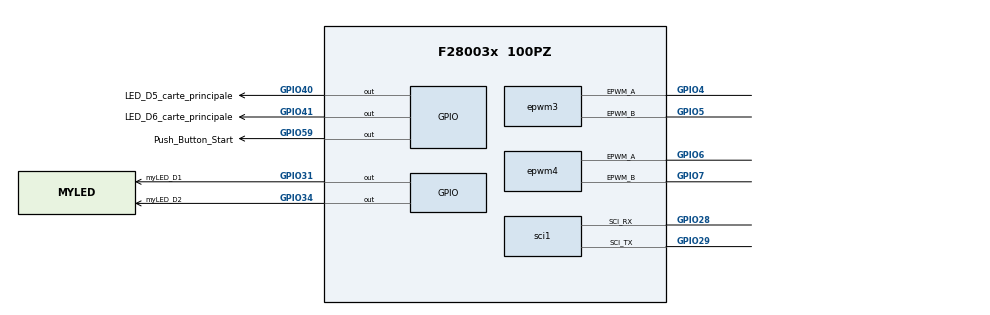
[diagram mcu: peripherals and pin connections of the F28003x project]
/**
 * @cliArgs --device "F28003x" --package "100PZ" --part "F28003x_100PZ" --context "system" --product "C2000WARE@5.02.00.00"
 * @versions {"tool":"1.19.0+3426"}
 */

/**
 * Import the modules used in this configuration.
 */
const adc              = scripting.addModule("/driverlib/adc.js", {}, false);
const adc1             = adc.addInstance();
const adc2             = adc.addInstance();
const asysctl          = scripting.addModule("/driverlib/asysctl.js");
const cputimer         = scripting.addModule("/driverlib/cputimer.js", {}, false);
const cputimer1        = cputimer.addInstance();
const epwm             = scripting.addModule("/driverlib/epwm.js", {}, false);
const epwm1            = epwm.addInstance();
const epwm2            = epwm.addInstance();
const epwm3            = epwm.addInstance();
const epwm4            = epwm.addInstance();
const gpio             = scripting.addModule("/driverlib/gpio.js", {}, false);
const gpio1            = gpio.addInstance();
const gpio2            = gpio.addInstance();
const gpio3            = gpio.addInstance();
const gpio4            = gpio.addInstance();
const gpio5            = gpio.addInstance();
const inputxbar        = scripting.addModule("/driverlib/inputxbar.js", {}, false);
const inputxbar1       = inputxbar.addInstance();
const inputxbar_input  = scripting.addModule("/driverlib/inputxbar_input.js");
const inputxbar_input1 = inputxbar_input.addInstance();
const inputxbar_input2 = inputxbar_input.addInstance();
const inputxbar_input3 = inputxbar_input.addInstance();
const sci              = scripting.addModule("/driverlib/sci.js", {}, false);
const sci1             = sci.addInstance();

/**
 * Write custom configuration values to the imported modules.
 */
adc1.$name                    = "myADC0";
adc1.adcClockPrescaler        = "ADC_CLK_DIV_2_0";
adc1.soc0Trigger              = "ADC_TRIGGER_CPU1_TINT0";
adc1.interruptPulseMode       = "ADC_PULSE_END_OF_CONV";
adc1.enabledInts              = ["ADC_INT_NUMBER1"];
adc1.registerInterrupts       = ["1"];
adc1.soc1Channel              = "ADC_CH_ADCIN1";
adc1.soc1SampleWindow         = 9;
adc1.soc1Trigger              = "ADC_TRIGGER_CPU1_TINT0";
adc1.enabledSOCs              = ["ADC_SOC_NUMBER0","ADC_SOC_NUMBER1","ADC_SOC_NUMBER2","ADC_SOC_NUMBER3"];
adc1.soc2Channel              = "ADC_CH_ADCIN2";
adc1.soc2Trigger              = "ADC_TRIGGER_CPU1_TINT0";
adc1.soc2SampleWindow         = 9;
adc1.soc3Channel              = "ADC_CH_ADCIN3";
adc1.soc3SampleWindow         = 9;
adc1.soc3Trigger              = "ADC_TRIGGER_CPU1_TINT0";
adc1.enableInterrupt1         = true;
adc1.soc0SampleWindow         = 9;
adc1.adcInt1.enableInterrupt  = true;
adc1.adcInt1.interruptHandler = "adcA1ISR";

adc2.$name              = "myADC1";
adc2.adcClockPrescaler  = "ADC_CLK_DIV_2_0";
adc2.soc0Trigger        = "ADC_TRIGGER_CPU1_TINT0";
adc2.soc0SampleWindow   = 9;
adc2.interruptPulseMode = "ADC_PULSE_END_OF_CONV";
adc2.enabledInts        = ["ADC_INT_NUMBER1"];
adc2.registerInterrupts = ["1"];
adc2.soc1Channel        = "ADC_CH_ADCIN1";
adc2.soc1SampleWindow   = 9;
adc2.soc1Trigger        = "ADC_TRIGGER_CPU1_TINT0";
adc2.enabledSOCs        = ["ADC_SOC_NUMBER0","ADC_SOC_NUMBER1","ADC_SOC_NUMBER2","ADC_SOC_NUMBER3"];
adc2.soc2Channel        = "ADC_CH_ADCIN2";
adc2.soc2Trigger        = "ADC_TRIGGER_CPU1_TINT0";
adc2.soc2SampleWindow   = 9;
adc2.soc3Channel        = "ADC_CH_ADCIN3";
adc2.soc3SampleWindow   = 9;
adc2.soc3Trigger        = "ADC_TRIGGER_CPU1_TINT0";
adc2.adcBase            = "ADCB_BASE";
adc2.useInterrupts      = false;

const analog  = scripting.addModule("/driverlib/analog.js", {}, false);
const analog1 = analog.addInstance({}, false);
analog1.$name = "myANALOGPinMux0";
adc1.analog   = analog1;
adc2.analog   = analog1;

asysctl.analogReference        = "INTERNAL";
asysctl.analogReferenceVoltage = "1P65";

cputimer1.$name           = "myCPUTIMER0";
cputimer1.emulationMode   = "CPUTIMER_EMULATIONMODE_STOPATZERO";
cputimer1.timerPrescaler  = 4;
cputimer1.startTimer      = true;
cputimer1.enableInterrupt = true;
cputimer1.timerPeriod     = 1000;

epwm1.hrpwm_edgeModeA                                          = "HRPWM_MEP_CTRL_FALLING_EDGE";
epwm1.hrpwm_edgeModeB                                          = "HRPWM_MEP_CTRL_FALLING_EDGE";
epwm1.epwmTimebase_counterMode                                 = "EPWM_COUNTER_MODE_UP";
epwm1.epwmActionQualifier_EPWM_AQ_OUTPUT_A_ON_TIMEBASE_ZERO    = "EPWM_AQ_OUTPUT_HIGH";
epwm1.epwmActionQualifier_EPWM_AQ_OUTPUT_A_ON_TIMEBASE_UP_CMPA = "EPWM_AQ_OUTPUT_LOW";
epwm1.epwmActionQualifier_EPWM_AQ_OUTPUT_B_ON_TIMEBASE_ZERO    = "EPWM_AQ_OUTPUT_HIGH";
epwm1.epwmActionQualifier_EPWM_AQ_OUTPUT_B_ON_TIMEBASE_UP_CMPA = "EPWM_AQ_OUTPUT_LOW";
epwm1.epwmTimebase_emulationMode                               = "EPWM_EMULATION_FREE_RUN";
epwm1.hrpwm_cmpaHR                                             = 50;
epwm1.hrpwm_cmpbHR                                             = 50;
epwm1.epwmDeadband_polarityFED                                 = "EPWM_DB_POLARITY_ACTIVE_LOW";
epwm1.epwmDeadband_delayRED                                    = 4;
epwm1.epwmDeadband_delayFED                                    = 4;
epwm1.epwmTimebase_clockDiv                                    = "EPWM_CLOCK_DIVIDER_8";
epwm1.epwmTimebase_hsClockDiv                                  = "EPWM_HSCLOCK_DIVIDER_1";
epwm1.epwmTimebase_period                                      = 599;
epwm1.epwmDeadband_dbControlGld                                = true;
epwm1.epwmDeadband_enableRED                                   = true;
epwm1.epwmDeadband_enableFED                                   = true;
epwm1.$name                                                    = "myEPWM1";
epwm1.epwm.$assign                                             = "EPWM1";

epwm2.hrpwm_edgeModeA                                          = "HRPWM_MEP_CTRL_FALLING_EDGE";
epwm2.hrpwm_edgeModeB                                          = "HRPWM_MEP_CTRL_FALLING_EDGE";
epwm2.epwmTimebase_counterMode                                 = "EPWM_COUNTER_MODE_UP";
epwm2.epwmActionQualifier_EPWM_AQ_OUTPUT_A_ON_TIMEBASE_ZERO    = "EPWM_AQ_OUTPUT_HIGH";
epwm2.epwmActionQualifier_EPWM_AQ_OUTPUT_A_ON_TIMEBASE_UP_CMPA = "EPWM_AQ_OUTPUT_LOW";
epwm2.epwmActionQualifier_EPWM_AQ_OUTPUT_B_ON_TIMEBASE_ZERO    = "EPWM_AQ_OUTPUT_HIGH";
epwm2.epwmActionQualifier_EPWM_AQ_OUTPUT_B_ON_TIMEBASE_UP_CMPA = "EPWM_AQ_OUTPUT_LOW";
epwm2.epwmTimebase_emulationMode                               = "EPWM_EMULATION_FREE_RUN";
epwm2.hrpwm_cmpaHR                                             = 50;
epwm2.hrpwm_cmpbHR                                             = 50;
epwm2.epwmDeadband_polarityFED                                 = "EPWM_DB_POLARITY_ACTIVE_LOW";
epwm2.epwmDeadband_delayRED                                    = 4;
epwm2.epwmDeadband_delayFED                                    = 4;
epwm2.epwmTimebase_clockDiv                                    = "EPWM_CLOCK_DIVIDER_8";
epwm2.epwmTimebase_hsClockDiv                                  = "EPWM_HSCLOCK_DIVIDER_1";
epwm2.epwmTimebase_period                                      = 599;
epwm2.epwmDeadband_dbControlGld                                = true;
epwm2.epwmDeadband_enableRED                                   = true;
epwm2.epwmDeadband_enableFED                                   = true;
epwm2.$name                                                    = "myEPWM2";
epwm2.epwm.$assign                                             = "EPWM2";

epwm3.hrpwm_edgeModeA                                          = "HRPWM_MEP_CTRL_FALLING_EDGE";
epwm3.hrpwm_edgeModeB                                          = "HRPWM_MEP_CTRL_FALLING_EDGE";
epwm3.epwmTimebase_counterMode                                 = "EPWM_COUNTER_MODE_UP";
epwm3.epwmActionQualifier_EPWM_AQ_OUTPUT_A_ON_TIMEBASE_ZERO    = "EPWM_AQ_OUTPUT_HIGH";
epwm3.epwmActionQualifier_EPWM_AQ_OUTPUT_A_ON_TIMEBASE_UP_CMPA = "EPWM_AQ_OUTPUT_LOW";
epwm3.epwmActionQualifier_EPWM_AQ_OUTPUT_B_ON_TIMEBASE_ZERO    = "EPWM_AQ_OUTPUT_HIGH";
epwm3.epwmActionQualifier_EPWM_AQ_OUTPUT_B_ON_TIMEBASE_UP_CMPA = "EPWM_AQ_OUTPUT_LOW";
epwm3.epwmTimebase_emulationMode                               = "EPWM_EMULATION_FREE_RUN";
epwm3.hrpwm_cmpaHR                                             = 50;
epwm3.hrpwm_cmpbHR                                             = 50;
epwm3.epwmDeadband_polarityFED                                 = "EPWM_DB_POLARITY_ACTIVE_LOW";
epwm3.epwmDeadband_delayRED                                    = 4;
epwm3.epwmDeadband_delayFED                                    = 4;
epwm3.epwmTimebase_clockDiv                                    = "EPWM_CLOCK_DIVIDER_8";
epwm3.epwmTimebase_hsClockDiv                                  = "EPWM_HSCLOCK_DIVIDER_1";
epwm3.epwmTimebase_period                                      = 599;
epwm3.epwmDeadband_dbControlGld                                = true;
epwm3.epwmDeadband_enableRED                                   = true;
epwm3.epwmDeadband_enableFED                                   = true;
epwm3.$name                                                    = "myEPWM3";
epwm3.epwm.$assign                                             = "EPWM3";
epwm3.epwm.epwm_aPin.$assign                                   = "GPIO4";
epwm3.epwm.epwm_bPin.$assign                                   = "GPIO5";

epwm4.hrpwm_edgeModeA                                          = "HRPWM_MEP_CTRL_FALLING_EDGE";
epwm4.hrpwm_edgeModeB                                          = "HRPWM_MEP_CTRL_FALLING_EDGE";
epwm4.epwmTimebase_counterMode                                 = "EPWM_COUNTER_MODE_UP";
epwm4.epwmActionQualifier_EPWM_AQ_OUTPUT_A_ON_TIMEBASE_ZERO    = "EPWM_AQ_OUTPUT_HIGH";
epwm4.epwmActionQualifier_EPWM_AQ_OUTPUT_A_ON_TIMEBASE_UP_CMPA = "EPWM_AQ_OUTPUT_LOW";
epwm4.epwmActionQualifier_EPWM_AQ_OUTPUT_B_ON_TIMEBASE_ZERO    = "EPWM_AQ_OUTPUT_HIGH";
epwm4.epwmActionQualifier_EPWM_AQ_OUTPUT_B_ON_TIMEBASE_UP_CMPA = "EPWM_AQ_OUTPUT_LOW";
epwm4.epwmTimebase_emulationMode                               = "EPWM_EMULATION_FREE_RUN";
epwm4.hrpwm_cmpaHR                                             = 50;
epwm4.hrpwm_cmpbHR                                             = 50;
epwm4.epwmDeadband_polarityFED                                 = "EPWM_DB_POLARITY_ACTIVE_LOW";
epwm4.epwmDeadband_delayRED                                    = 4;
epwm4.epwmDeadband_delayFED                                    = 4;
epwm4.epwmTimebase_clockDiv                                    = "EPWM_CLOCK_DIVIDER_8";
epwm4.epwmTimebase_hsClockDiv                                  = "EPWM_HSCLOCK_DIVIDER_1";
epwm4.epwmTimebase_period                                      = 599;
epwm4.epwmDeadband_dbControlGld                                = true;
epwm4.epwmDeadband_enableRED                                   = true;
epwm4.epwmDeadband_enableFED                                   = true;
epwm4.$name                                                    = "myEPWM4";
epwm4.epwm.$assign                                             = "EPWM4";
epwm4.epwm.epwm_aPin.$assign                                   = "GPIO6";
epwm4.epwm.epwm_bPin.$assign                                   = "GPIO7";

gpio1.direction       = "GPIO_DIR_MODE_OUT";
gpio1.$name           = "myLED_D1";
gpio1.gpioPin.$assign = "GPIO31";

gpio2.$name           = "myLED_D2";
gpio2.direction       = "GPIO_DIR_MODE_OUT";
gpio2.gpioPin.$assign = "GPIO34";

gpio3.$name           = "LED_D5_carte_principale";
gpio3.direction       = "GPIO_DIR_MODE_OUT";
gpio3.gpioPin.$assign = "GPIO40";

gpio4.$name           = "LED_D6_carte_principale";
gpio4.direction       = "GPIO_DIR_MODE_OUT";
gpio4.gpioPin.$assign = "GPIO41";

gpio5.$name                     = "Push_Button_Start";
gpio5.padConfig                 = "PULLUP";
gpio5.useInterrupt              = true;
gpio5.gpioPin.$assign           = "GPIO59";
gpio5.xint.enableInt            = true;
gpio5.xint.registerInterrupts   = true;
gpio5.xint.xInt.enableInterrupt = true;

inputxbar1.$name = "myINPUTXBAR5";

inputxbar_input1.$name          = "myINPUTXBARINPUT0";
inputxbar_input1.inputxbarInput = "XBAR_INPUT5";
inputxbar_input1.inputxbarGpio  = "GPIO40";

inputxbar_input2.$name          = "myINPUTXBARINPUT1";
inputxbar_input2.inputxbarInput = "XBAR_INPUT6";
inputxbar_input2.inputxbarGpio  = "GPIO40";

inputxbar_input3.$name         = "myINPUTXBARINPUT2";
gpio5.xint.inputxbar           = inputxbar_input3;
inputxbar_input3.inputxbarGpio = "GPIO59";
inputxbar_input3.inputxbarLock = true;

sci1.$name                    = "mySCI0";
sci1.registerInterrupts       = true;
sci1.rxFifo                   = "SCI_FIFO_RX1";
sci1.sci.sci_rxPin.$assign    = "GPIO28";
sci1.sci.sci_txPin.$assign    = "GPIO29";
sci1.sciRXInt.enableInterrupt = true;
sci1.sciTXInt.enableInterrupt = true;

/**
 * Pinmux solution for unlocked pins/peripherals. This ensures that minor changes to the automatic solver in a future
 * version of the tool will not impact the pinmux you originally saw.  These lines can be completely deleted in order to
 * re-solve from scratch.
 */
analog1.analog.$suggestSolution                           = "ANALOG";
analog1.analog["a0/b15/c15/daca_outPin"].$suggestSolution = "A0/B15/C15/DACA_OUT";
analog1.analog["a1/b7/dacb_outPin"].$suggestSolution      = "A1/B7/DACB_OUT";
analog1.analog["a10/b1/c10Pin"].$suggestSolution          = "A10/B1/C10";
analog1.analog["a11/b10/c0Pin"].$suggestSolution          = "A11/B10/C0";
analog1.analog["a12, c5Pin"].$suggestSolution             = "A12, C5";
analog1.analog["a14/b14/c4Pin"].$suggestSolution          = "A14/B14/C4";
analog1.analog["a2/b6/c9Pin"].$suggestSolution            = "A2/B6/C9";
analog1.analog["a3, c7/b9Pin"].$suggestSolution           = "A3, C7/B9";
analog1.analog["a4/b8Pin"].$suggestSolution               = "A4/B8";
analog1.analog.a5Pin.$suggestSolution                     = "A5";
analog1.analog.a6Pin.$suggestSolution                     = "A6";
analog1.analog.a8Pin.$suggestSolution                     = "A8";
analog1.analog.a9Pin.$suggestSolution                     = "A9";
analog1.analog["b0/c11Pin"].$suggestSolution              = "B0/C11";
analog1.analog.b11Pin.$suggestSolution                    = "B11";
analog1.analog["b11, gpio21Pin"].$suggestSolution         = "B11, GPIO21";
analog1.analog["b2/c6Pin"].$suggestSolution               = "B2/C6";
analog1.analog["b3/vdacPin"].$suggestSolution             = "B3/VDAC";
analog1.analog["b4/c8Pin"].$suggestSolution               = "B4/C8";
analog1.analog.b5Pin.$suggestSolution                     = "B5";
analog1.analog["b5, gpio20Pin"].$suggestSolution          = "B5, GPIO20";
analog1.analog.c1Pin.$suggestSolution                     = "C1";
analog1.analog.c14Pin.$suggestSolution                    = "C14";
analog1.analog["c2/b12Pin"].$suggestSolution              = "C2/B12";
analog1.analog["c3/a7Pin"].$suggestSolution               = "C3/A7";
epwm1.epwm.epwm_aPin.$suggestSolution                     = "GPIO0";
epwm1.epwm.epwm_bPin.$suggestSolution                     = "GPIO1";
epwm2.epwm.epwm_aPin.$suggestSolution                     = "GPIO2";
epwm2.epwm.epwm_bPin.$suggestSolution                     = "GPIO3";
sci1.sci.$suggestSolution                                 = "SCIA";
